# STM32MP157 register map
File version: 1.7
CPU: CM4 r0p1, little endian, no MPU, FPU, 4 interrupt priority bits
Registers are 32-bit, read-write, reset 0x0 unless marked. A register's access mark holds for its fields unless they carry their own. Offsets are from the block's base; [hi:lo] are bit positions; {n}, {i} and the like mark numbered series; 'fields as' and 'values as' point back to an identical list.

## DTS — DTS register block
Base 0x50028000
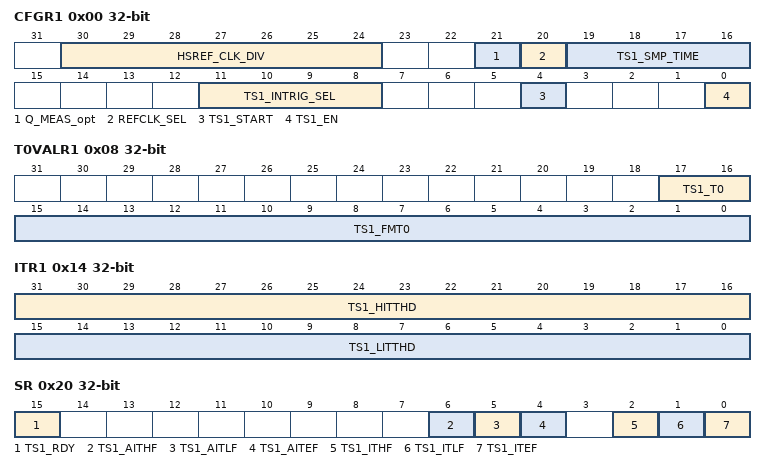
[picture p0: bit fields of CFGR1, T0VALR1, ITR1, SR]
0x00 CFGR1 — DTS_CFGR1 is the configuration register for temperature sensor 1.
  [30:24] HSREF_CLK_DIV, [21] Q_MEAS_opt, [20] REFCLK_SEL, [19:16] TS1_SMP_TIME, [11:8] TS1_INTRIG_SEL, [4] TS1_START, [0] TS1_EN
0x08 T0VALR1 ro — DTS_T0VALR1 contains the value of the factory calibration temperature (T0) for temperature sensor 1. The system reset value is factory trimmed.
  [17:16] TS1_T0, [15:0] TS1_FMT0
0x10 RAMPVALR ro — The DTS_RAMPVALR is the ramp coefficient for the temperature sensor. The system reset value is factory trimmed.
  [15:0] TS1_RAMP_COEFF
0x14 ITR1 — DTS_ITR1 contains the threshold values for sensor 1.
  [31:16] TS1_HITTHD, [15:0] TS1_LITTHD
0x1C DR — The DTS_DR contains the number of REF_CLK cycles used to compute the FM(T) frequency.
  [15:0] TS1_MFREQ
0x20 SR ro — Temperature sensor status register
  [15] TS1_RDY, [6] TS1_AITHF, [5] TS1_AITLF, [4] TS1_AITEF, [2] TS1_ITHF, [1] TS1_ITLF, [0] TS1_ITEF
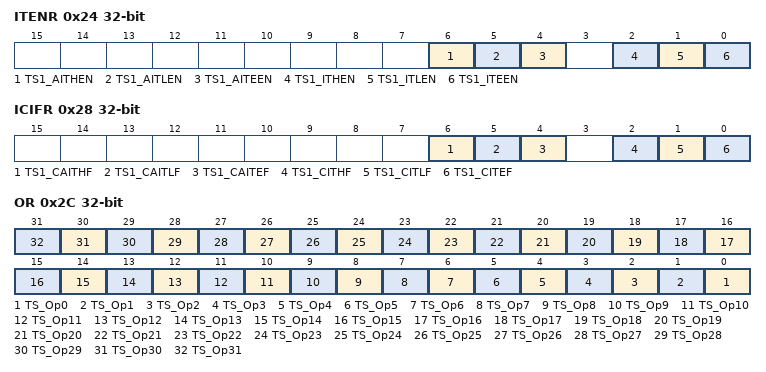
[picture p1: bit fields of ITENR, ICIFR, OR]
0x24 ITENR — Temperature sensor interrupt enable register
  [6] TS1_AITHEN, [5] TS1_AITLEN, [4] TS1_AITEEN, [2] TS1_ITHEN, [1] TS1_ITLEN, [0] TS1_ITEEN
0x28 ICIFR — DTS_ICIFR is the control register for the interrupt flags.
  [6] TS1_CAITHF, [5] TS1_CAITLF, [4] TS1_CAITEF, [2] TS1_CITHF, [1] TS1_CITLF, [0] TS1_CITEF
0x2C OR — The DTS_OR contains general-purpose option bits.
  [n] TS_Op{n} (n=0..31)

## ETH_MTL
Base 0x5800AC00
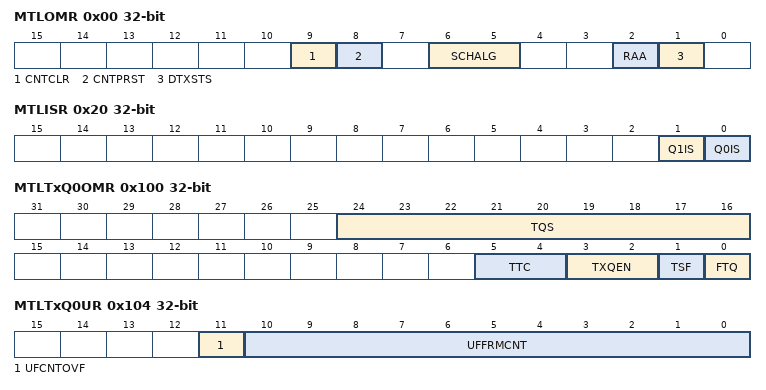
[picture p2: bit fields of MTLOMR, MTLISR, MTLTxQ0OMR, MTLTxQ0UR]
0x00 MTLOMR — The Operating Mode register establishes the Transmit and Receive operating modes and commands.
  [9] CNTCLR, [8] CNTPRST, [6:5] SCHALG, [2] RAA, [1] DTXSTS
0x20 MTLISR ro — The software driver (application) reads this register during interrupt service routine or polling to determine the interrupt status of MTL queues and the MAC.
  [1] Q1IS, [0] Q0IS
0x100 MTLTxQ0OMR — Tx queue 0 operating mode Register
  [24:16] TQS, [5:4] TTC, [3:2] TXQEN, [1] TSF, [0] FTQ
0x104 MTLTxQ0UR ro — Tx queue 0 underflow register
  [11] UFCNTOVF, [10:0] UFFRMCNT
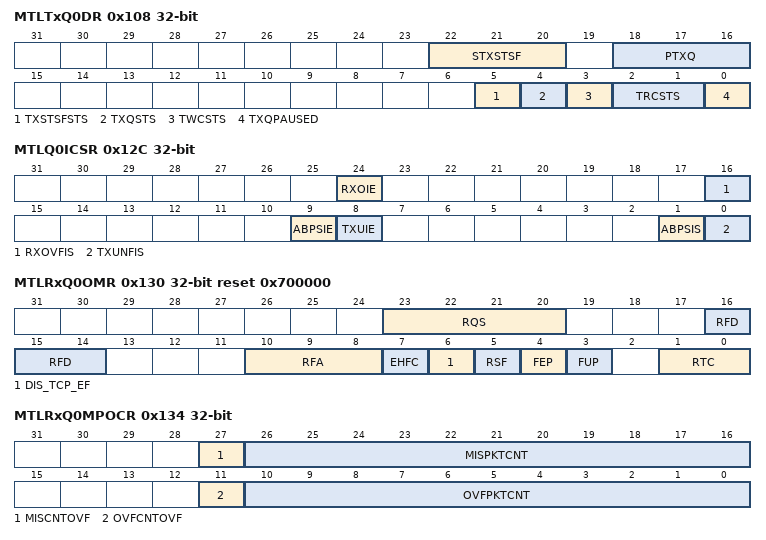
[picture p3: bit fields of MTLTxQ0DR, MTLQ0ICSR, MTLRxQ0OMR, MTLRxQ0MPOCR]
0x108 MTLTxQ0DR ro — Tx queue 0 underflow register
  [22:20] STXSTSF, [18:16] PTXQ, [5] TXSTSFSTS, [4] TXQSTS, [3] TWCSTS, [2:1] TRCSTS, [0] TXQPAUSED
0x114 MTLTxQ0ESR ro — Tx queue x ETS status Register
  [23:0] ABS
0x12C MTLQ0ICSR — Queue 0 interrupt control status Register
  [24] RXOIE, [16] RXOVFIS, [9] ABPSIE, [8] TXUIE, [1] ABPSIS, [0] TXUNFIS ro
0x130 MTLRxQ0OMR reset 0x700000 — Rx queue 0 operating mode register
  [23:20] RQS ro, [16:14] RFD, [10:8] RFA, [7] EHFC, [6] DIS_TCP_EF, [5] RSF, [4] FEP, [3] FUP, [1:0] RTC
0x134 MTLRxQ0MPOCR ro — Rx queue 0 missed packet and overflow counter register
  [27] MISCNTOVF, [26:16] MISPKTCNT, [11] OVFCNTOVF, [10:0] OVFPKTCNT
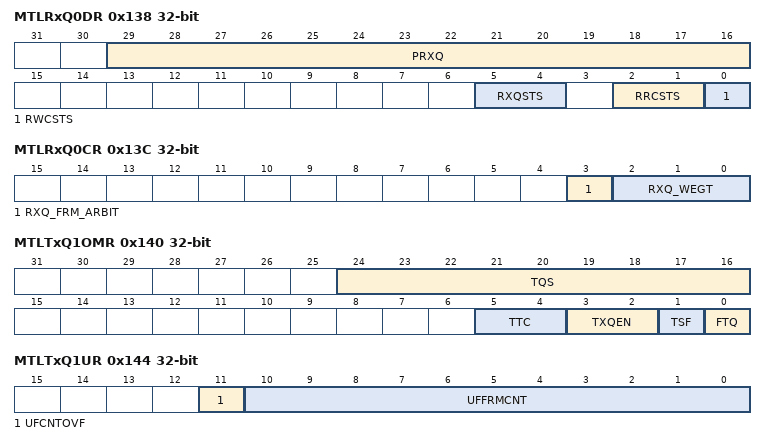
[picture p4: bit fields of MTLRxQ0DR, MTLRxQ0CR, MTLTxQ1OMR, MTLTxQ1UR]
0x138 MTLRxQ0DR ro — Rx queue i debug register
  [29:16] PRXQ, [5:4] RXQSTS, [2:1] RRCSTS, [0] RWCSTS
0x13C MTLRxQ0CR — Rx queue 0 control register
  [3] RXQ_FRM_ARBIT ro, [2:0] RXQ_WEGT ro
0x140 MTLTxQ1OMR — Tx queue 1 operating mode Register
  [24:16] TQS, [5:4] TTC, [3:2] TXQEN, [1] TSF, [0] FTQ
0x144 MTLTxQ1UR ro — Tx queue 1 underflow register
  [11] UFCNTOVF, [10:0] UFFRMCNT
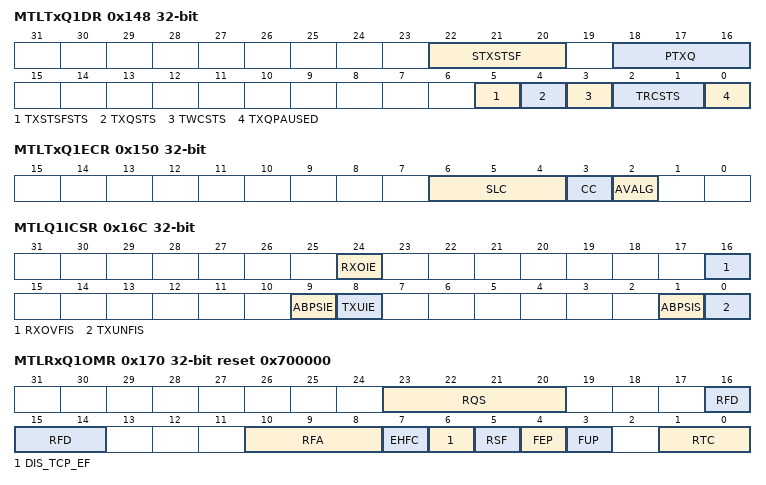
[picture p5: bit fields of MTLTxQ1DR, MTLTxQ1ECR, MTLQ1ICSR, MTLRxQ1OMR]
0x148 MTLTxQ1DR ro — Tx queue 1 underflow register
  fields as MTLTxQ0DR
0x150 MTLTxQ1ECR — The Queue ETS Control register controls the enhanced transmission selection operation.
  [6:4] SLC, [3] CC, [2] AVALG
0x154 MTLTxQ1ESR ro — Tx queue x ETS status Register
  [23:0] ABS
0x158 MTLTxQ1QWR — This register provides the average traffic transmitted on queue 1.
  [20:0] ISCQW
0x15C MTLTxQ1SSCR — The sendSlopeCredit register contains the sendSlope credit value required for the credit-based shaper algorithm for the Queue.
  [13:0] SSC
0x160 MTLTxQ1HCR — The hiCredit register contains the hiCredit value required for the credit-based shaper algorithm for the Queue.
  [28:0] HC
0x164 MTLTxQ1LCR — The loCredit register contains the loCredit value required for the credit-based shaper algorithm for the Queue.
  [28:0] LC
0x16C MTLQ1ICSR — Queue 1 interrupt control status Register
  fields as MTLQ0ICSR
0x170 MTLRxQ1OMR reset 0x700000 — Rx queue 1 operating mode register
  fields as MTLRxQ0OMR
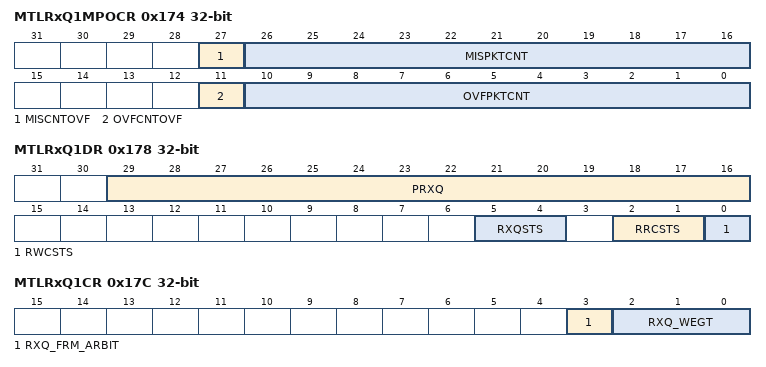
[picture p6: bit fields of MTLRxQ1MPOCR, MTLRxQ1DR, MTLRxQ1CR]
0x174 MTLRxQ1MPOCR ro — Rx queue 1 missed packet and overflow counter register
  [27] MISCNTOVF, [26:16] MISPKTCNT, [11] OVFCNTOVF, [10:0] OVFPKTCNT
0x178 MTLRxQ1DR ro — Rx queue i debug register
  [29:16] PRXQ, [5:4] RXQSTS, [2:1] RRCSTS, [0] RWCSTS
0x17C MTLRxQ1CR — Rx queue 1 control register
  [3] RXQ_FRM_ARBIT ro, [2:0] RXQ_WEGT ro
